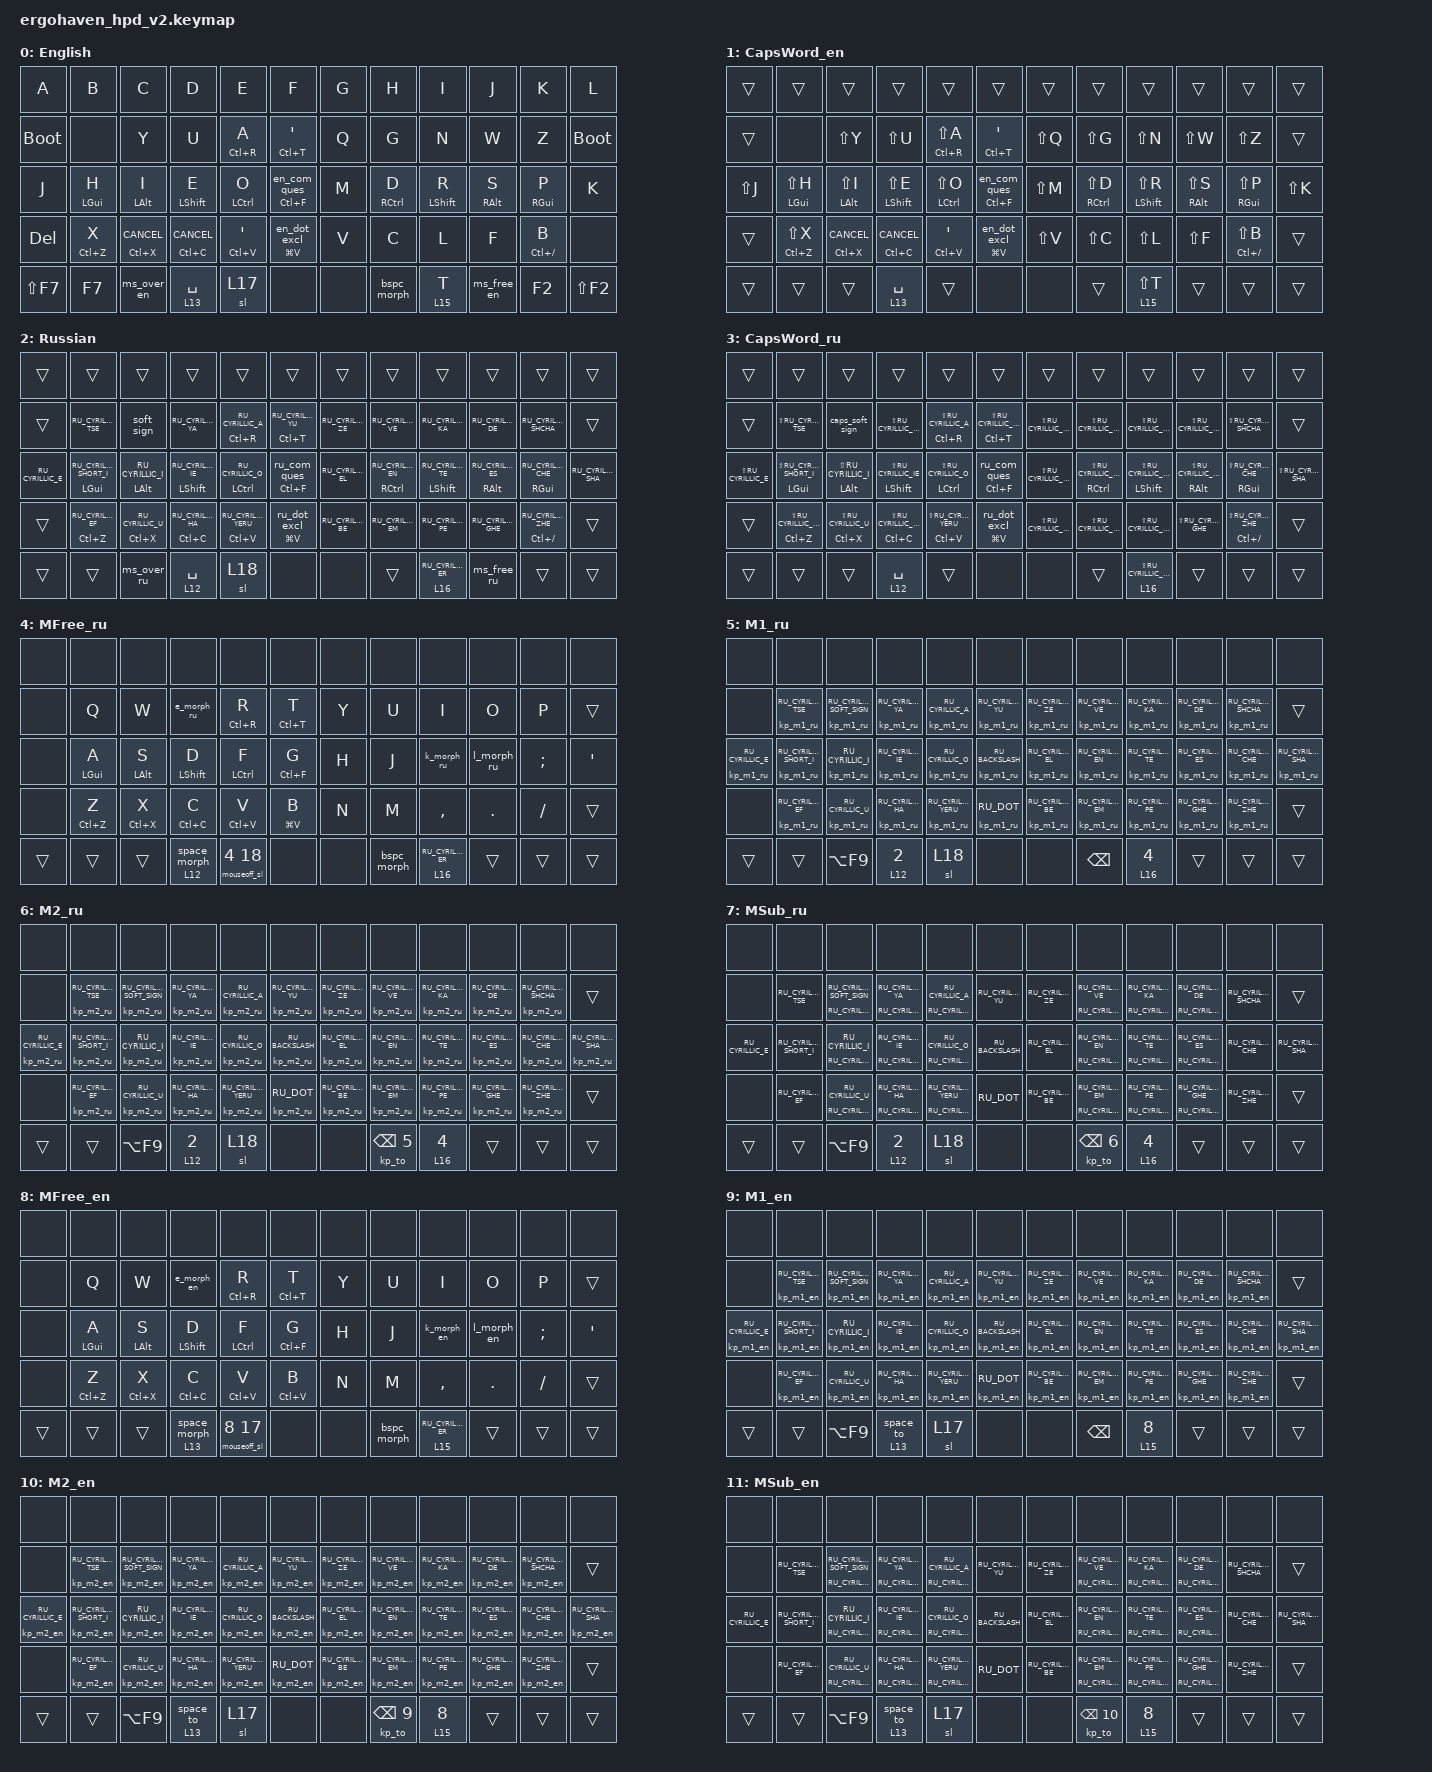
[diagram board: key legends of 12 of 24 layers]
#include "keys_ru.h"
#include <dt-bindings/zmk/behaviors.h>
#include <behaviors.dtsi>
#include <dt-bindings/zmk/keys.h>

&mt {
    flavor = "tap-preferred";
    tapping-term-ms = <200>;
    bindings = <&kp>, <&long_kp>;
};

&lt {
    flavor = "balanced";
    bindings = <&mo>, <&long_kp>;
};

&sl {
    release-after-ms = <5000>;
    ignore-modifiers;
};

&sk {
    release-after-ms = <30000>;
    quick-release;
};

&key_repeat { usage-pages = <HID_USAGE_KEY HID_USAGE_CONSUMER>; };

/ {
    combos {
        compatible = "zmk,combos";

        combo_ctrl_ent {
            bindings = <&long_kp LC(ENTER)>;
            key-positions = <2 4>;
            require-prior-idle-ms = <30>;
        };

        combo_enter {
            bindings = <&long_kp ENTER>;
            key-positions = <3 2>;
            require-prior-idle-ms = <30>;
            timeout-ms = <30>;
        };

        combo_tab {
            bindings = <&long_kp TAB>;
            key-positions = <14 15>;
            require-prior-idle-ms = <50>;
            timeout-ms = <30>;
        };

        combo_esc {
            bindings = <&long_kp ESC>;
            key-positions = <26 27>;
            require-prior-idle-ms = <30>;
            timeout-ms = <30>;
        };

        combo_ru {
            bindings = <&layer_ru>;
            key-positions = <15 16>;
            timeout-ms = <30>;
            require-prior-idle-ms = <50>;
        };

        combo_en {
            bindings = <&layer_en>;
            key-positions = <19 20>;
            timeout-ms = <30>;
            require-prior-idle-ms = <50>;
        };

        combo_osl_sym_en {
            bindings = <&sl 19>;
            key-positions = <21 20>;
            require-prior-idle-ms = <50>;
            layers = <0 1 19>;
            timeout-ms = <30>;
        };

        combo_lessgreater_en {
            bindings = <&less_greater_en>;
            require-prior-idle-ms = <30>;
            key-positions = <31 33>;
            layers = <0 1 19>;
        };

        combo_osl_sym_ru {
            bindings = <&sl 20>;
            key-positions = <20 21>;
            require-prior-idle-ms = <50>;
            layers = <2 3 20>;
            timeout-ms = <30>;
        };

        combo_lessgreater_ru {
            bindings = <&less_greater_ru>;
            key-positions = <31 33>;
            require-prior-idle-ms = <30>;
            layers = <2 3>;
        };

        combo_braces_en {
            bindings = <&braces_en>;
            key-positions = <19 21>;
            require-prior-idle-ms = <50>;
            layers = <0 1 19>;
        };

        combo_asterisk_ru {
            bindings = <&kp RU_ASTERISK>;
            timeout-ms = <30>;
            key-positions = <7 9 8>;
            layers = <2 3 20 16>;
        };

        combo_asterisk_en {
            bindings = <&kp ASTERISK>;
            timeout-ms = <30>;
            key-positions = <7 8 9>;
            layers = <0 1 15 19>;
        };

        combo_capsword_en {
            bindings = <&to 1>;
            key-positions = <14 13>;
            layers = <0 1>;
        };

        combo_osl_fn {
            bindings = <&sl 21>;
            key-positions = <26 28>;
        };

        combo_osl_os_en {
            bindings = <&sl 23>;
            key-positions = <25 26>;
            layers = <0 1 15 19 23 8 9 10 11 17>;
        };

        combo_capsword_ru {
            bindings = <&to 3>;
            key-positions = <14 13>;
            layers = <2 3>;
        };

        combo_plus {
            bindings = <&kp PLUS>;
            key-positions = <7 8>;
        };

        parentheses {
            bindings = <&parentheses>;
            key-positions = <14 16>;
            timeout-ms = <30>;
            require-prior-idle-ms = <50>;
        };

        combo_braces_ru {
            bindings = <&braces_ru>;
            key-positions = <19 21>;
            timeout-ms = <25>;
            layers = <2 3 20>;
            require-prior-idle-ms = <50>;
        };

        combo_brackets_en {
            bindings = <&brackets_en>;
            key-positions = <7 9>;
            layers = <0 1 19>;
            timeout-ms = <30>;
            require-prior-idle-ms = <30>;
        };

        combo_brackets_ru {
            bindings = <&brackets_ru>;
            key-positions = <7 9>;
            layers = <2 3 20>;
            timeout-ms = <30>;
        };

        combo_minus {
            bindings = <&kp MINUS>;
            key-positions = <31 32>;
            require-prior-idle-ms = <30>;
            timeout-ms = <30>;
        };

        combo_ru_at {
            bindings = <&en_kp AT>;
            key-positions = <14 15 16>;
            layers = <2 3 20>;
        };

        combo_en_at {
            bindings = <&kp AT>;
            key-positions = <16 15 14>;
            layers = <0 1 19>;
        };

        combo_quotes_en {
            bindings = <&quote_morph_en>;
            key-positions = <27 28>;
            layers = <0 1 15 19>;
        };

        combo_quotes_ru {
            bindings = <&quote_morph_ru>;
            key-positions = <27 28>;
            layers = <2 3 20 16>;
        };

        combo_slash_ru {
            bindings = <&slash_morph_ru>;
            key-positions = <3 4>;
            layers = <2 3 16 20>;
        };

        combo_slash_en {
            bindings = <&slash_morph_en>;
            key-positions = <3 4>;
            layers = <0 1 15 19>;
        };

        combo_arrow_ru {
            bindings = <&arrow_ru>;
            key-positions = <31 32 33>;
            layers = <2 3 16 20>;
        };

        combo_arrow_en {
            bindings = <&arrow_en>;
            key-positions = <31 33 32>;
            layers = <0 1 15 19>;
        };

        combo_and_ru {
            bindings = <&en_kp AMPERSAND>;
            key-positions = <2 3 4>;
            layers = <2 3 16 20>;
        };

        combo_and_en {
            bindings = <&kp AMPERSAND>;
            key-positions = <2 3 4>;
            layers = <0 1 15 19>;
        };

        combo_dollar_ru {
            bindings = <&en_kp DOLLAR>;
            key-positions = <19 20 21>;
            layers = <2 3 16 20>;
        };

        combo_dollar_en {
            bindings = <&kp DOLLAR>;
            key-positions = <19 20 21>;
            layers = <0 1 15 19>;
        };

        combo_hash_ru {
            bindings = <&en_kp HASH>;
            key-positions = <26 27 28>;
            layers = <2 3 16 20>;
        };

        combo_hash_en {
            bindings = <&kp HASH>;
            key-positions = <26 27 28>;
            layers = <0 1 15 19>;
        };

        cmb_osl_os_ru {
            bindings = <&sl 22>;
            key-positions = <25 26>;
            layers = <2 3 16 20 22 4 5 6 7 18>;
        };

        combo_equal {
            bindings = <&kp EQUAL>;
            key-positions = <8 9>;
        };

        combo_under {
            bindings = <&kp UNDER>;
            key-positions = <32 33>;
        };
    };

    macros {
        layer_ru: layer_ru {
            compatible = "zmk,behavior-macro";
            #binding-cells = <0>;
            bindings = <&kp LS(LC(N8)) &mouse_off &to 2>;
            label = "LAYER_RU";
        };

        layer_en: layer_en {
            compatible = "zmk,behavior-macro";
            #binding-cells = <0>;
            bindings = <&kp LS(LC(N9)) &mouse_off &to 0>;
            label = "LAYER_EN";
        };

        lg_ru: lg_ru {
            compatible = "zmk,behavior-macro";
            #binding-cells = <0>;
            bindings = <&kp LS(LC(N8))>;
            label = "LG_RU";
        };

        lg_en: lg_en {
            compatible = "zmk,behavior-macro";
            #binding-cells = <0>;
            bindings = <&kp LS(LC(N9))>;
            label = "LG_EN";
        };

        en_kp: en_kp {
            compatible = "zmk,behavior-macro-one-param";
            #binding-cells = <1>;
            bindings = <&kp LS(LC(N9)) &macro_param_1to1 &kp MACRO_PLACEHOLDER &kp LS(LC(N8))>;
            label = "EN_KP";
        };

        ru_kp: ru_kp {
            compatible = "zmk,behavior-macro-one-param";
            #binding-cells = <1>;
            bindings = <&kp LS(LC(N8)) &macro_param_1to1 &kp MACRO_PLACEHOLDER &kp LS(LC(N9))>;
            label = "RU_KP";
        };

        mouse_off: mouse_off {
            compatible = "zmk,behavior-macro";
            #binding-cells = <0>;
            bindings = <&kp LA(F12)>;
            label = "MOUSE_OFF";
        };

        free: free {
            compatible = "zmk,behavior-macro";
            #binding-cells = <0>;
            bindings = <&kp LA(F10)>;
            label = "FREE";
        };

        overlay: overlay {
            compatible = "zmk,behavior-macro";
            #binding-cells = <0>;
            bindings = <&kp LA(F11)>;
            label = "OVERLAY";
        };

        select_row: select_row {
            compatible = "zmk,behavior-macro";
            #binding-cells = <0>;
            bindings = <&kp END &kp LS(HOME)>;
            label = "SELECT_ROW";
            wait-ms = <0>;
        };

        en_code: en_code_block {
            compatible = "zmk,behavior-macro";
            #binding-cells = <0>;
            bindings = <&kp GRAVE &kp GRAVE &kp GRAVE &kp RETURN &kp RET &kp GRAVE &kp GRAVE &kp GRAVE &kp UP_ARROW>;
            label = "EN_CODE_BLOCK";
            tap-ms = <50>;
        };

        ru_code: ru_code {
            compatible = "zmk,behavior-macro";
            #binding-cells = <0>;
            bindings = <&lg_en &kp GRAVE &kp GRAVE &kp GRAVE &kp RETURN &kp RET &kp GRAVE &kp GRAVE &kp GRAVE &kp UP_ARROW &lg_ru>;
            label = "RU_CODE";
            tap-ms = <50>;
            wait-ms = <10>;
        };

        ru_cw_off: ru_cw_off {
            compatible = "zmk,behavior-macro-one-param";
            #binding-cells = <1>;
            bindings = <&macro_param_1to1 &kp MACRO_PLACEHOLDER &to 2>;
            label = "RU_CW_OFF";
            wait-ms = <0>;
        };

        en_cw_off: en_cw_off {
            compatible = "zmk,behavior-macro-one-param";
            #binding-cells = <1>;
            bindings = <&macro_param_1to1 &kp MACRO_PLACEHOLDER &to 0>;
            label = "EN_CW_OFF";
            wait-ms = <0>;
        };

        zeros_macro: zeros_macro {
            compatible = "zmk,behavior-macro";
            #binding-cells = <0>;
            bindings = <&kp N0 &kp N0 &kp N0 &kp N0 &kp N0 &kp N0>;
            label = "ZEROS_MACRO";
        };

        ml: ml {
            compatible = "zmk,behavior-macro-one-param";
            #binding-cells = <1>;
            bindings =
                <&macro_param_1to1 &key_on MACRO_PLACEHOLDER &layer_on 14>,
                <&macro_pause_for_release>,
                <&macro_param_1to1 &key_off MACRO_PLACEHOLDER &layer_off 14>;

            label = "Mod Layer";
            wait-ms = <0>;
            tap-ms = <0>;
        };

        quotes_ru: dbl_quote {
            compatible = "zmk,behavior-macro";
            #binding-cells = <0>;
            bindings = <&kp LS(NUMBER_2) &kp LS(NUMBER_2) &kp LEFT_ARROW>;
            label = "DBL_QUOTE";
            wait-ms = <0>;
        };

        quotes_en: quotes_en {
            compatible = "zmk,behavior-macro";
            #binding-cells = <0>;
            bindings = <&kp DOUBLE_QUOTES &kp DOUBLE_QUOTES &kp LEFT_ARROW>;
            label = "QUOTES_EN";
            wait-ms = <0>;
        };

        braces_en: braces_en {
            compatible = "zmk,behavior-macro";
            #binding-cells = <0>;
            bindings = <&kp LEFT_BRACE &kp RIGHT_BRACE &kp LEFT>;
            label = "BRACES_EN";
            wait-ms = <0>;
        };

        braces_ru: braces_ru {
            compatible = "zmk,behavior-macro";
            #binding-cells = <0>;
            bindings = <&lg_en &braces_en &lg_ru>;
            label = "BRACES_RU";
            wait-ms = <0>;
        };

        brackets_en: brackets_en {
            compatible = "zmk,behavior-macro";
            #binding-cells = <0>;
            bindings = <&kp LEFT_BRACKET &kp RIGHT_BRACKET &kp LEFT_ARROW>;
            label = "BRACKETS_EN";
            wait-ms = <0>;
        };

        brackets_ru: brackets_ru {
            compatible = "zmk,behavior-macro";
            #binding-cells = <0>;
            bindings = <&lg_en &brackets_en &lg_ru>;
            label = "BRACKETS_RU";
            wait-ms = <0>;
        };

        parentheses: parentheses {
            compatible = "zmk,behavior-macro";
            #binding-cells = <0>;
            bindings = <&kp LEFT_PARENTHESIS &kp RIGHT_PARENTHESIS &kp LEFT_ARROW>;
            label = "PARENTHESES";
            wait-ms = <0>;
        };

        less_greater_en: less_greater_en {
            compatible = "zmk,behavior-macro";
            #binding-cells = <0>;
            bindings = <&kp LESS_THAN &kp GREATER_THAN &kp LEFT>;
            label = "LESS_GREATER_EN";
            wait-ms = <0>;
        };

        less_greater_ru: less_greater_ru {
            compatible = "zmk,behavior-macro";
            #binding-cells = <0>;
            bindings = <&lg_en &less_greater_en &lg_ru>;
            label = "LESS_GREATER_RU";
        };

        alt_spc_ru: alt_spc_ru {
            compatible = "zmk,behavior-macro";
            #binding-cells = <0>;
            bindings = <&mouse_off &kp LA(SPACE) &to 2>;
            label = "ALT_SPC_RU";
            wait-ms = <0>;
            tap-ms = <40>;
        };

        kp_layeroff: cancel_msoff {
            compatible = "zmk,behavior-macro-two-param";
            #binding-cells = <2>;
            bindings = <&macro_param_1to1 &layer_off MACRO_PLACEHOLDER &macro_param_2to1 &kp MACRO_PLACEHOLDER>;
            label = "CANCEL_MSOFF";
        };

        kp_: kp_ {
            compatible = "zmk,behavior-macro-one-param";
            #binding-cells = <1>;
            bindings =
                <&macro_press>,
                <&macro_param_1to1 &kp MACRO_PLACEHOLDER>,
                <&macro_pause_for_release>,
                <&macro_release>,
                <&macro_param_1to1 &kp MACRO_PLACEHOLDER>;

            label = "KP_";
        };

        testops: testops {
            compatible = "zmk,behavior-macro";
            #binding-cells = <0>;
            bindings =
                <&kp LS(LC(LG(F7)))>,
                <&macro_wait_time 100>,
                <&kp LEFT_ARROW &kp LS(LC(LG(F8)))>;

            label = "TESTOPS";
            wait-ms = <350>;
            tap-ms = <150>;
        };

        long_kp: long_kp {
            compatible = "zmk,behavior-macro-one-param";
            #binding-cells = <1>;
            bindings =
                <&macro_press>,
                <&macro_param_1to1 &kp MACRO_PLACEHOLDER>,
                <&macro_pause_for_release>,
                <&macro_release>,
                <&macro_param_1to1 &kp MACRO_PLACEHOLDER>;

            label = "LONG_KP";
            wait-ms = <50>;
        };

        arrow_en: arrow_en {
            compatible = "zmk,behavior-macro";
            #binding-cells = <0>;
            bindings = <&kp MINUS &kp GREATER_THAN>;
            label = "ARROW_EN";
        };

        arrow_ru: arrow_ru {
            compatible = "zmk,behavior-macro";
            #binding-cells = <0>;
            bindings = <&lg_en &arrow_en &lg_ru>;
            label = "ARROW_RU";
        };

        one_shot: one_shot {
            compatible = "zmk,behavior-macro-one-param";
            #binding-cells = <1>;
            bindings =
                <&macro_param_1to1 &sk MACRO_PLACEHOLDER>,
                <&macro_pause_for_release>,
                <&kp K_CANCEL>;

            label = "ONE_SHOT";
            tap-ms = <10>;
        };

        vm_lang_ru: vm_lang {
            compatible = "zmk,behavior-macro-one-param";
            #binding-cells = <1>;
            bindings = <&macro_param_1to1 &kp MACRO_PLACEHOLDER &lg_ru &lg_ru>;
            label = "VM_LANG";
            wait-ms = <100>;
            tap-ms = <100>;
        };

        vm_lang_en: vm_lang_en {
            compatible = "zmk,behavior-macro-one-param";
            #binding-cells = <1>;
            bindings = <&macro_param_1to1 &kp MACRO_PLACEHOLDER &lg_en &lg_en>;
            label = "VM_LANG_EN";
            wait-ms = <100>;
            tap-ms = <100>;
        };

        ms_free_ru: macro_mless_free {
            compatible = "zmk,behavior-macro";
            #binding-cells = <0>;
            bindings = <&free &to 4>;
            label = "MACRO_MLESS_FREE";
        };

        ms_over_ru: macro_mless_over {
            compatible = "zmk,behavior-macro";
            #binding-cells = <0>;
            bindings = <&overlay &to 5>;
            label = "MACRO_MLESS_OVER";
        };

        ms_free_en: ms_free_en {
            compatible = "zmk,behavior-macro";
            #binding-cells = <0>;
            bindings = <&free &to 8>;
            label = "ms_free_en";
        };

        ms_over_en: ms_over_en {
            compatible = "zmk,behavior-macro";
            #binding-cells = <0>;
            bindings = <&overlay &to 9>;
            label = "ms_over_en";
        };

        kp_m1_ru: kp_m1_ru {
            compatible = "zmk,behavior-macro-one-param";
            #binding-cells = <1>;
            bindings = <&macro_param_1to1 &kp MACRO_PLACEHOLDER &to 6>;
            label = "KP_M1_RU";
        };

        kp_m2_ru: kp_m2_ru {
            compatible = "zmk,behavior-macro-one-param";
            #binding-cells = <1>;
            bindings = <&macro_param_1to1 &kp MACRO_PLACEHOLDER &to 7>;
            label = "kp_m2_ru";
        };

        kp_sub_ru: kp_sub_ru {
            compatible = "zmk,behavior-macro-one-param";
            #binding-cells = <1>;
            bindings = <&macro_param_1to1 &kp MACRO_PLACEHOLDER &to 2>;
            label = "kp_sub_ru";
        };

        kp_to: kp_to {
            compatible = "zmk,behavior-macro-two-param";
            #binding-cells = <2>;
            bindings = <&macro_param_1to1 &kp MACRO_PLACEHOLDER &macro_param_2to1 &to MACRO_PLACEHOLDER>;
            label = "KP_TO";
        };

        kp_m1_en: kp_m1_en {
            compatible = "zmk,behavior-macro-one-param";
            #binding-cells = <1>;
            bindings = <&macro_param_1to1 &kp MACRO_PLACEHOLDER &to 10>;
            label = "KP_M1_EN";
        };

        kp_m2_en: kp_m2_en {
            compatible = "zmk,behavior-macro-one-param";
            #binding-cells = <1>;
            bindings = <&macro_param_1to1 &kp MACRO_PLACEHOLDER &to 11>;
            label = "KP_M2_EN";
        };

        kp_sub_en: kp_sub_en {
            compatible = "zmk,behavior-macro-one-param";
            #binding-cells = <1>;
            bindings = <&macro_param_1to1 &kp MACRO_PLACEHOLDER &to 0>;
            label = "KP_SUB_EN";
        };

        r_to: r_to {
            compatible = "zmk,behavior-macro-one-param";
            #binding-cells = <1>;
            bindings = <&long_kp RU_CYRILLIC_ER &macro_param_1to1 &to MACRO_PLACEHOLDER>;
            label = "R_TO";
        };

        space_to: space_to {
            compatible = "zmk,behavior-macro-one-param";
            #binding-cells = <1>;
            bindings = <&long_kp SPACE &macro_param_1to1 &to MACRO_PLACEHOLDER>;
            label = "SPACE_TO";
        };

        free_move_to: free_move_to {
            compatible = "zmk,behavior-macro-one-param";
            #binding-cells = <1>;
            bindings = <&kp MINUS &free &macro_param_1to1 &to MACRO_PLACEHOLDER>;
            label = "FREE_MOVE_TO";
        };

        alt_spc_en: alt_spc_en {
            compatible = "zmk,behavior-macro";
            #binding-cells = <0>;
            bindings = <&mouse_off &kp LA(SPACE) &to 0>;
            label = "ALT_SPC_EN";
            wait-ms = <0>;
            tap-ms = <40>;
        };

        kp_free: kp_free {
            compatible = "zmk,behavior-macro-one-param";
            #binding-cells = <1>;
            bindings = <&macro_param_1to1 &kp MACRO_PLACEHOLDER &free>;
            label = "KP_FREE";
        };

        mouseoff_sl: mouseoff_sl {
            compatible = "zmk,behavior-macro-two-param";
            #binding-cells = <2>;
            bindings = <&mouse_off &macro_param_1to1 &layer_off MACRO_PLACEHOLDER &macro_param_2to1 &sl MACRO_PLACEHOLDER>;
            label = "MOUSEOFF_SL";
        };

        mouseoff_kp_ru: mouseoff_kp_ru {
            compatible = "zmk,behavior-macro-one-param";
            #binding-cells = <1>;
            bindings = <&mouse_off &macro_param_1to1 &kp MACRO_PLACEHOLDER &to 2>;
            label = "MOUSEOFF_KP_RU";
        };

        mouseoff_kp_en: mouseoff_kp_en {
            compatible = "zmk,behavior-macro-one-param";
            #binding-cells = <1>;
            bindings = <&mouse_off &macro_param_1to1 &kp MACRO_PLACEHOLDER &to 0>;
            label = "MOUSEOFF_KP_EN";
        };

        free_kp: free_kp {
            compatible = "zmk,behavior-macro-one-param";
            #binding-cells = <1>;
            bindings = <&mouse_off &macro_param_1to1 &kp MACRO_PLACEHOLDER &free>;
            label = "FREE_KP";
            wait-ms = <0>;
        };

        drag_sub_ru: drag_sub_ru {
            compatible = "zmk,behavior-macro-one-param";
            #binding-cells = <1>;
            bindings = <&sticky_drag N0 &macro_param_1to1 &kp MACRO_PLACEHOLDER &to 5>;
            label = "DRAG_SUB_RU";
        };

        drag_sub_en: drag_sub_en {
            compatible = "zmk,behavior-macro-one-param";
            #binding-cells = <1>;
            bindings = <&sticky_drag N0 &macro_param_1to1 &kp MACRO_PLACEHOLDER &to 9>;
            label = "DRAG_SUB_EN";
        };
    };

    behaviors {
        layer_off: layer_off {
            compatible = "zmk,behavior-toggle-layer";
            label = "LAYER_OFF";
            #binding-cells = <1>;
            toggle-mode = "off";
        };

        hrm: hrm {
            compatible = "zmk,behavior-hold-tap";
            label = "Home Row Mod";
            bindings = <&kp>, <&kp>;

            #binding-cells = <2>;
            tapping-term-ms = <200>;
            flavor = "balanced";
        };

        hrm_slow: hrm_slow {
            compatible = "zmk,behavior-hold-tap";
            label = "HRM for slow fingers";
            bindings = <&kp>, <&kp>;

            #binding-cells = <2>;
            flavor = "tap-preferred";
            tapping-term-ms = <200>;
        };

        ru_lt_cw_off: ru_lt_cw_off {
            compatible = "zmk,behavior-hold-tap";
            label = "RU_LT_CW_OFF";
            bindings = <&mo>, <&ru_cw_off>;

            #binding-cells = <2>;
            tapping-term-ms = <180>;
            flavor = "balanced";
        };

        en_lt_cw_off: en_lt_cw_off {
            compatible = "zmk,behavior-hold-tap";
            label = "EN_LT_CW_OFF";
            bindings = <&mo>, <&en_cw_off>;

            #binding-cells = <2>;
            tapping-term-ms = <180>;
            flavor = "balanced";
        };

        bspc_morph: bspc_morph {
            compatible = "zmk,behavior-mod-morph";
            label = "BSPC_MORPH";
            bindings = <&kp BACKSPACE>, <&kp DELETE>;

            #binding-cells = <0>;
            mods = <(MOD_LALT)>;
        };

        key_on: key_on {
            compatible = "zmk,behavior-key-toggle";
            label = "KEY_ON";
            #binding-cells = <1>;
        };

        key_off: key_off {
            compatible = "zmk,behavior-key-toggle";
            label = "KEY_OFF";
            #binding-cells = <1>;
            toggle-mode = "off";
        };

        hrml: hrml {
            compatible = "zmk,behavior-hold-tap";
            label = "Home Row Mod Layer";
            bindings = <&ml>, <&kp>;

            #binding-cells = <2>;
            tapping-term-ms = <200>;
            flavor = "balanced";
            hold-trigger-key-positions = <1 2 3 5 6 7 8 9 10 12 13 14 15 16 17 18 19 20 21 22 23 25 26 27 28 29 30 31 32 33 34 42 39 41>;
        };

        layer_on: layer_on {
            compatible = "zmk,behavior-toggle-layer";
            label = "LAYER_ON";
            #binding-cells = <1>;
            toggle-mode = "on";
        };

        hrml_slow: hrml_slow {
            compatible = "zmk,behavior-hold-tap";
            label = "HRML for slow fingers";
            bindings = <&ml>, <&kp>;

            #binding-cells = <2>;
            tapping-term-ms = <200>;
            flavor = "tap-preferred";
        };

        soft_sign: soft_sign {
            compatible = "zmk,behavior-mod-morph";
            label = "SOFT_SIGN";
            bindings = <&kp RU_CYRILLIC_SOFT_SIGN>, <&kp RU_CYRILLIC_HARD_SIGN>;

            #binding-cells = <0>;
            mods = <(MOD_LSFT)>;
        };

        en_dot_excl: en_dot_excl {
            compatible = "zmk,behavior-mod-morph";
            label = "EN_DOT_EXCL";
            bindings = <&morph_en_dot>, <&en_cw_off COLON>;

            #binding-cells = <0>;
            mods = <(MOD_RALT)>;
        };

        en_com_ques: en_com_ques {
            compatible = "zmk,behavior-mod-morph";
            label = "EN_COM_QUES";
            bindings = <&morph_en_com>, <&en_cw_off SEMI>;

            #binding-cells = <0>;
            mods = <(MOD_RALT)>;
        };

        ru_dot_excl: ru_dot_excl {
            compatible = "zmk,behavior-mod-morph";
            label = "RU_DOT_EXCL";
            bindings = <&morph_ru_dot>, <&ru_cw_off RU_COLON>;

            #binding-cells = <0>;
            mods = <(MOD_RALT)>;
        };

        ru_com_ques: ru_com_ques {
            compatible = "zmk,behavior-mod-morph";
            label = "RU_COM_QUES";
            bindings = <&morph_ru_com>, <&ru_cw_off RU_SEMI>;

            #binding-cells = <0>;
            mods = <(MOD_RALT)>;
        };

        ru_dot_mt: ru_dot_mt {
            compatible = "zmk,behavior-hold-tap";
            label = "RU_DOT_MT";
            bindings = <&kp>, <&ru_dot_excl>;

            #binding-cells = <2>;
            tapping-term-ms = <200>;
            flavor = "tap-preferred";
        };

        ru_com_mt: ru_com_mt {
            compatible = "zmk,behavior-hold-tap";
            label = "RU_COM_MT";
            bindings = <&kp>, <&ru_com_ques>;

            #binding-cells = <2>;
            tapping-term-ms = <200>;
            flavor = "tap-preferred";
        };

        en_com_mt: en_com_mt {
            compatible = "zmk,behavior-hold-tap";
            label = "EN_COM_MT";
            bindings = <&kp>, <&en_com_ques>;

            #binding-cells = <2>;
            tapping-term-ms = <200>;
            flavor = "balanced";
        };

        en_dot_mt: en_dot_mt {
            compatible = "zmk,behavior-hold-tap";
            label = "EN_DOT_MT";
            bindings = <&kp>, <&en_dot_excl>;

            #binding-cells = <2>;
            tapping-term-ms = <200>;
            flavor = "balanced";
        };

        space_morph: space_morph {
            compatible = "zmk,behavior-mod-morph";
            label = "SPACE_MORPH";
            bindings = <&kp SPACE>, <&kp TAB>;

            #binding-cells = <0>;
            mods = <(MOD_RSFT|MOD_LALT|MOD_LSFT|MOD_RALT|MOD_LCTL|MOD_RGUI|MOD_RCTL|MOD_LGUI)>;
            keep-mods = <(MOD_LSFT|MOD_RSFT|MOD_LALT|MOD_RALT|MOD_LCTL|MOD_RGUI|MOD_LGUI|MOD_RCTL)>;
        };

        caps_soft_sign: caps_soft_sign {
            compatible = "zmk,behavior-mod-morph";
            label = "CAPS_SOFT_SIGN";
            bindings =
                <&kp LS(RU_CYRILLIC_SOFT_SIGN)>,
                <&kp LS(RU_CYRILLIC_HARD_SIGN)>;

            #binding-cells = <0>;
            mods = <(MOD_LSFT)>;
        };

        space_lt: space_lt {
            compatible = "zmk,behavior-hold-tap";
            label = "SPACE_LT";
            bindings = <&mo>, <&space_morph>;

            #binding-cells = <2>;
            tapping-term-ms = <200>;
            flavor = "balanced";
        };

        mod_dtap: mod_dtap {
            compatible = "zmk,behavior-hold-tap";
            label = "MOD_DTAP";
            bindings = <&kp>, <&kp>;

            #binding-cells = <2>;
            tapping-term-ms = <180>;
            flavor = "hold-preferred";
        };

        hrosm_l: hrosm_l {
            compatible = "zmk,behavior-hold-tap";
            label = "HROSM_L";
            bindings = <&one_shot>, <&kp>;

            #binding-cells = <2>;
            tapping-term-ms = <200>;
            flavor = "balanced";
            hold-trigger-key-positions = <6 18 30 31 32 33 42 19 7 8 20 9 21 22 10 34 23>;
        };

        hrosm_r: hrosm_r {
            compatible = "zmk,behavior-hold-tap";
            label = "HROSM_R";
            bindings = <&one_shot>, <&kp>;

            #binding-cells = <2>;
            tapping-term-ms = <200>;
            flavor = "balanced";
            hold-trigger-key-positions = <12 1 13 25 26 27 28 29 17 16 4 5 3 15 2 14>;
        };

        vm_en: vm_en {
            compatible = "zmk,behavior-hold-tap";
            label = "VM_EN";
            bindings = <&vm_lang_en>, <&vm_lang_en>;

            #binding-cells = <2>;
            tapping-term-ms = <200>;
            flavor = "tap-preferred";
        };

        vm_ru: vm_ru {
            compatible = "zmk,behavior-hold-tap";
            label = "VM_RU";
            bindings = <&vm_lang_ru>, <&vm_lang_ru>;

            #binding-cells = <2>;
            tapping-term-ms = <200>;
            flavor = "tap-preferred";
        };

        space_nav_to: space_nav_to {
            compatible = "zmk,behavior-hold-tap";
            label = "SPACE_NAV_TO";
            bindings = <&mo>, <&space_to>;

            #binding-cells = <2>;
            tapping-term-ms = <200>;
            flavor = "balanced";
        };

        move_nav: move_nav {
            compatible = "zmk,behavior-hold-tap";
            label = "MOVE_NAV";
            bindings = <&mo>, <&free_move_to>;

            #binding-cells = <2>;
            tapping-term-ms = <200>;
            flavor = "balanced";
        };

        sticky_drag: sticky_drag {
            compatible = "zmk,behavior-sticky-key";
            label = "STICKY_DRAG";
            bindings = <&kp>;
            #binding-cells = <1>;
            release-after-ms = <10000>;
            ignore-modifiers;
        };

        mt_mouseoff_ru: mt_mouseoff_ru {
            compatible = "zmk,behavior-hold-tap";
            label = "MT_MOUSEOFF_RU";
            bindings = <&mouseoff_kp_ru>, <&kp>;

            #binding-cells = <2>;
            tapping-term-ms = <200>;
            flavor = "tap-preferred";
        };

        mt_mouseoff_en: mt_mouseoff_en {
            compatible = "zmk,behavior-hold-tap";
            label = "MT_MOUSEOFF_EN";
            bindings = <&mouseoff_kp_en>, <&kp>;

            #binding-cells = <2>;
            tapping-term-ms = <200>;
            flavor = "tap-preferred";
        };

        mt_free: mt_free {
            compatible = "zmk,behavior-hold-tap";
            label = "MT_FREE";
            bindings = <&free_kp>, <&kp>;

            #binding-cells = <2>;
            tapping-term-ms = <200>;
            flavor = "tap-preferred";
        };

        l_morph_ru: l_morph_ru {
            compatible = "zmk,behavior-mod-morph";
            label = "L_MORPH_RU";
            bindings = <&kp L>, <&mouseoff_kp_ru LC(L)>;

            #binding-cells = <0>;
            mods = <(MOD_LCTL)>;
        };

        l_morph_en: l_morph_en {
            compatible = "zmk,behavior-mod-morph";
            label = "L_MORPH_EN";
            bindings = <&kp L>, <&mouseoff_kp_en LC(L)>;

            #binding-cells = <0>;
            mods = <(MOD_LCTL)>;
        };

        e_morph_ru: e_morph_ru {
            compatible = "zmk,behavior-mod-morph";
            label = "E_MORPH_RU";
            bindings = <&kp E>, <&mouseoff_kp_ru LC(E)>;

            #binding-cells = <0>;
            mods = <(MOD_LCTL)>;
        };

        e_morph_en: e_morph_en {
            compatible = "zmk,behavior-mod-morph";
            label = "E_MORPH_EN";
            bindings = <&kp E>, <&mouseoff_kp_en LC(E)>;

            #binding-cells = <0>;
            mods = <(MOD_LCTL)>;
        };

        k_morph_ru: k_morph_ru {
            compatible = "zmk,behavior-mod-morph";
            label = "K_MORPH_RU";
            bindings = <&kp K>, <&mouseoff_kp_ru LC(K)>;

            #binding-cells = <0>;
            mods = <(MOD_LCTL)>;
        };

        k_morph_en: k_morph_en {
            compatible = "zmk,behavior-mod-morph";
            label = "K_MORPH_EN";
            bindings = <&kp K>, <&mouseoff_kp_en LC(K)>;

            #binding-cells = <0>;
            mods = <(MOD_LCTL)>;
        };

        slash_morph_ru: slash_morph_ru {
            compatible = "zmk,behavior-mod-morph";
            label = "SLASH_MORPH_RU";
            bindings = <&morph_pipe_ru>, <&kp RU_BACKSLASH>;

            #binding-cells = <0>;
            mods = <(MOD_LSFT)>;
        };

        slash_morph_en: slash_morph_en {
            compatible = "zmk,behavior-mod-morph";
            label = "SLASH_MORPH_EN";
            bindings = <&morph_pipe_en>, <&kp BACKSLASH>;

            #binding-cells = <0>;
            mods = <(MOD_LSFT)>;
        };

        quote_morph_ru: quote_morph_ru {
            compatible = "zmk,behavior-mod-morph";
            label = "QUOTE_MORPH_RU";
            bindings = <&morph_quotes_ru>, <&en_kp SINGLE_QUOTE>;

            #binding-cells = <0>;
            mods = <(MOD_LSFT)>;
        };

        quote_morph_en: quote_morph_en {
            compatible = "zmk,behavior-mod-morph";
            label = "QUOTE_MORPH_EN";
            bindings = <&morph_quotes_en>, <&kp SINGLE_QUOTE>;

            #binding-cells = <0>;
            mods = <(MOD_LSFT)>;
        };

        mt_sub_ru: mt_sub_ru {
            compatible = "zmk,behavior-hold-tap";
            label = "MT_SUB_RU";
            bindings = <&drag_sub_ru>, <&kp_sub_ru>;

            #binding-cells = <2>;
            tapping-term-ms = <200>;
            flavor = "tap-preferred";
        };

        mt_sub_en: mt_sub_en {
            compatible = "zmk,behavior-hold-tap";
            label = "MT_SUB_EN";
            bindings = <&drag_sub_en>, <&kp_sub_en>;

            #binding-cells = <2>;
            tapping-term-ms = <200>;
            flavor = "tap-preferred";
        };

        semi_morph_ru: semi_morph_ru {
            compatible = "zmk,behavior-mod-morph";
            label = "SEMI_MORPH_RU";
            bindings = <&kp RU_SEMI>, <&kp RU_COLON>;

            #binding-cells = <0>;
            mods = <(MOD_LSFT)>;
        };

        semi_morph_en: semi_morph_en {
            compatible = "zmk,behavior-mod-morph";
            label = "SEMI_MORPH_EN";
            bindings = <&kp SEMI>, <&kp COLON>;

            #binding-cells = <0>;
            mods = <(MOD_LSFT)>;
        };

        morph_en_dot: morph_en_dot {
            compatible = "zmk,behavior-mod-morph";
            label = "MORPH_EN_DOT";
            bindings = <&en_cw_off DOT>, <&en_cw_off EXCL>;

            #binding-cells = <0>;
            mods = <(MOD_LSFT)>;
        };

        morph_en_com: morph_en_com {
            compatible = "zmk,behavior-mod-morph";
            label = "MORPH_EN_COM";
            bindings = <&en_cw_off COMMA>, <&en_cw_off QUESTION>;

            #binding-cells = <0>;
            mods = <(MOD_LSFT)>;
        };

        morph_ru_dot: morph_ru_dot {
            compatible = "zmk,behavior-mod-morph";
            label = "MORPH_RU_DOT";
            bindings = <&ru_cw_off RU_DOT>, <&ru_cw_off RU_EXCL>;

            #binding-cells = <0>;
            mods = <(MOD_LSFT)>;
        };

        morph_ru_com: morph_ru_com {
            compatible = "zmk,behavior-mod-morph";
            label = "MORPH_RU_COM";
            bindings = <&ru_cw_off RU_COMMA>, <&ru_cw_off RU_QUESTION>;

            #binding-cells = <0>;
            mods = <(MOD_LSFT)>;
        };

        morph_quotes_ru: morph_quotes_ru {
            compatible = "zmk,behavior-mod-morph";
            label = "MORPH_QUOTES_RU";
            bindings = <&kp RU_DQT>, <&en_kp GRAVE>;

            #binding-cells = <0>;
            mods = <(MOD_RALT)>;
        };

        morph_quotes_en: morph_quotes_en {
            compatible = "zmk,behavior-mod-morph";
            label = "MORPH_QUOTES_EN";
            bindings = <&kp DQT>, <&kp GRAVE>;

            #binding-cells = <0>;
            mods = <(MOD_RALT)>;
        };

        morph_pipe_ru: morph_pipe_ru {
            compatible = "zmk,behavior-mod-morph";
            label = "MORPH_PIPE_RU";
            bindings = <&kp RU_SLASH>, <&en_kp PIPE>;

            #binding-cells = <0>;
            mods = <(MOD_RALT)>;
        };

        morph_pipe_en: morph_pipe_en {
            compatible = "zmk,behavior-mod-morph";
            label = "MORPH_PIPE_EN";
            bindings = <&kp SLASH>, <&kp PIPE>;

            #binding-cells = <0>;
            mods = <(MOD_RALT)>;
        };
    };

    keymap {
        compatible = "zmk,keymap";

        En {
            bindings = <
&kp A        &kp B                  &kp C                  &kp D                  &kp E          &kp F                   &kp G  &kp H               &kp I                  &kp J            &kp K              &kp L
&bootloader  &none                  &kp Y                  &kp U                  &mt LC(R) A    &mt LC(T) APOS          &kp Q  &kp G               &kp N                  &kp W            &kp Z              &bootloader
&kp J        &hrml_slow LEFT_GUI H  &hrml_slow LEFT_ALT I  &hrosm_l LEFT_SHIFT E  &hrml LCTRL O  &en_com_mt LC(F) 0      &kp M  &hrml_slow RCTRL D  &hrosm_r LEFT_SHIFT R  &hrosm_r RALT S  &hrml_slow RGUI P  &kp K
&kp DELETE   &mt LC(Z) X            &mt LC(X) K_CANCEL     &mt LC(C) K_CANCEL     &mt LC(V) SQT  &en_dot_mt LG(V) 0      &kp V  &kp C               &kp L                  &kp F            &mt LC(SLASH) B    &none
&kp LS(F7)   &kp F7                 &ms_over_en            &lt 13 SPACE           &sl 17         &none                   &none  &bspc_morph         &lt 15 T               &ms_free_en      &kp F2             &kp LS(F2)
            >;

            display-name = "English";
        };

        En_CW {
            bindings = <
&trans     &trans                     &trans                     &trans                     &trans             &trans                  &trans     &trans                  &trans                     &trans               &trans                 &trans
&trans     &none                      &kp LS(Y)                  &kp LS(U)                  &mt LC(R) LS(A)    &mt LC(T) APOS          &kp LS(Q)  &kp LS(G)               &kp LS(N)                  &kp LS(W)            &kp LS(Z)              &trans
&kp LS(J)  &hrml_slow LEFT_GUI LS(H)  &hrml_slow LEFT_ALT LS(I)  &hrosm_l LEFT_SHIFT LS(E)  &hrml LCTRL LS(O)  &en_com_mt LC(F) 0      &kp LS(M)  &hrml_slow RCTRL LS(D)  &hrosm_r LEFT_SHIFT LS(R)  &hrosm_r RALT LS(S)  &hrml_slow RGUI LS(P)  &kp LS(K)
&trans     &mt LC(Z) LS(X)            &mt LC(X) K_CANCEL         &mt LC(C) K_CANCEL         &mt LC(V) SQT      &en_dot_mt LG(V) 0      &kp LS(V)  &kp LS(C)               &kp LS(L)                  &kp LS(F)            &mt LC(SLASH) LS(B)    &trans
&trans     &trans                     &trans                     &en_lt_cw_off 13 SPACE     &trans             &none                   &none      &trans                  &lt 15 LS(T)               &trans               &trans                 &trans
            >;

            display-name = "CapsWord_en";
        };

        Ru {
            bindings = <
&trans             &trans                                   &trans                             &trans                              &trans                      &trans                        &trans              &trans                           &trans                              &trans                        &trans                           &trans
&trans             &kp RU_CYRILLIC_TSE                      &soft_sign                         &kp RU_CYRILLIC_YA                  &mt LC(R) RU_CYRILLIC_A     &mt LC(T) RU_CYRILLIC_YU      &kp RU_CYRILLIC_ZE  &kp RU_CYRILLIC_VE               &kp RU_CYRILLIC_KA                  &kp RU_CYRILLIC_DE            &kp RU_CYRILLIC_SHCHA            &trans
&kp RU_CYRILLIC_E  &hrml_slow LEFT_GUI RU_CYRILLIC_SHORT_I  &hrml_slow LEFT_ALT RU_CYRILLIC_I  &hrosm_l LEFT_SHIFT RU_CYRILLIC_IE  &hrml LCTRL RU_CYRILLIC_O   &ru_com_mt LC(F) 0            &kp RU_CYRILLIC_EL  &hrml_slow RCTRL RU_CYRILLIC_EN  &hrosm_r LEFT_SHIFT RU_CYRILLIC_TE  &hrosm_r RALT RU_CYRILLIC_ES  &hrml_slow RGUI RU_CYRILLIC_CHE  &kp RU_CYRILLIC_SHA
&trans             &mt LC(Z) RU_CYRILLIC_EF                 &mt LC(X) RU_CYRILLIC_U            &mt LC(C) RU_CYRILLIC_HA            &mt LC(V) RU_CYRILLIC_YERU  &ru_dot_mt LG(V) 0            &kp RU_CYRILLIC_BE  &kp RU_CYRILLIC_EM               &kp RU_CYRILLIC_PE                  &kp RU_CYRILLIC_GHE           &mt LC(SLASH) RU_CYRILLIC_ZHE    &trans
&trans             &trans                                   &ms_over_ru                        &lt 12 SPACE                        &sl 18                      &none                         &none               &trans                           &lt 16 RU_CYRILLIC_ER               &ms_free_ru                   &trans                           &trans
            >;

            display-name = "Russian";
        };

        Ru_CW {
            bindings = <
&trans                 &trans                                       &trans                                 &trans                                  &trans                          &trans                            &trans                  &trans                               &trans                                  &trans                            &trans                               &trans
&trans                 &kp LS(RU_CYRILLIC_TSE)                      &caps_soft_sign                        &kp LS(RU_CYRILLIC_YA)                  &mt LC(R) LS(RU_CYRILLIC_A)     &mt LC(T) LS(RU_CYRILLIC_YU)      &kp LS(RU_CYRILLIC_ZE)  &kp LS(RU_CYRILLIC_VE)               &kp LS(RU_CYRILLIC_KA)                  &kp LS(RU_CYRILLIC_DE)            &kp LS(RU_CYRILLIC_SHCHA)            &trans
&kp LS(RU_CYRILLIC_E)  &hrml_slow LEFT_GUI LS(RU_CYRILLIC_SHORT_I)  &hrml_slow LEFT_ALT LS(RU_CYRILLIC_I)  &hrosm_l LEFT_SHIFT LS(RU_CYRILLIC_IE)  &hrml LCTRL LS(RU_CYRILLIC_O)   &ru_com_mt LC(F) 0                &kp LS(RU_CYRILLIC_EL)  &hrml_slow RCTRL LS(RU_CYRILLIC_EN)  &hrosm_r LEFT_SHIFT LS(RU_CYRILLIC_TE)  &hrosm_r RALT LS(RU_CYRILLIC_ES)  &hrml_slow RGUI LS(RU_CYRILLIC_CHE)  &kp LS(RU_CYRILLIC_SHA)
&trans                 &mt LC(Z) LS(RU_CYRILLIC_EF)                 &mt LC(X) LS(RU_CYRILLIC_U)            &mt LC(C) LS(RU_CYRILLIC_HA)            &mt LC(V) LS(RU_CYRILLIC_YERU)  &ru_dot_mt LG(V) 0                &kp LS(RU_CYRILLIC_BE)  &kp LS(RU_CYRILLIC_EM)               &kp LS(RU_CYRILLIC_PE)                  &kp LS(RU_CYRILLIC_GHE)           &mt LC(SLASH) LS(RU_CYRILLIC_ZHE)    &trans
&trans                 &trans                                       &trans                                 &ru_lt_cw_off 12 SPACE                  &trans                          &none                             &none                   &trans                               &lt 16 LS(RU_CYRILLIC_ER)               &trans                            &trans                               &trans
            >;

            display-name = "CapsWord_ru";
        };

        MFree_ru {
            bindings = <
&none   &none                 &none             &none              &none              &none                        &none  &none        &none                  &none        &none      &none
&none   &kp Q                 &kp W             &e_morph_ru        &mt_free LC(R) R   &mt_mouseoff_ru LC(T) T      &kp Y  &kp U        &kp I                  &kp O        &kp P      &trans
&none   &hrm_slow LEFT_GUI A  &hrm_slow LALT S  &hrm_slow LSHFT D  &hrm LCTRL F       &mt_mouseoff_ru LC(F) G      &kp H  &kp J        &k_morph_ru            &l_morph_ru  &kp SEMI   &kp SQT
&none   &mt_free LC(Z) Z      &mt_free LC(X) X  &mt_free LC(C) C   &mt_free LC(V) V   &mt_mouseoff_ru LG(V) B      &kp N  &kp M        &kp COMMA              &kp DOT      &kp SLASH  &trans
&trans  &trans                &trans            &space_lt 12 0     &mouseoff_sl 4 18  &none                        &none  &bspc_morph  &lt 16 RU_CYRILLIC_ER  &trans       &trans     &trans
            >;

            display-name = "MFree_ru";
        };

        M1_ru {
            display-name = "M1_ru";
            bindings = <
&none                    &none                          &none                            &none                     &none                       &none                         &none                     &none                     &none                     &none                      &none                        &none
&none                    &kp_m1_ru RU_CYRILLIC_TSE      &kp_m1_ru RU_CYRILLIC_SOFT_SIGN  &kp_m1_ru RU_CYRILLIC_YA  &kp_m1_ru RU_CYRILLIC_A     &kp_m1_ru RU_CYRILLIC_YU      &kp_m1_ru RU_CYRILLIC_ZE  &kp_m1_ru RU_CYRILLIC_VE  &kp_m1_ru RU_CYRILLIC_KA  &kp_m1_ru RU_CYRILLIC_DE   &kp_m1_ru RU_CYRILLIC_SHCHA  &trans
&kp_m1_ru RU_CYRILLIC_E  &kp_m1_ru RU_CYRILLIC_SHORT_I  &kp_m1_ru RU_CYRILLIC_I          &kp_m1_ru RU_CYRILLIC_IE  &kp_m1_ru RU_CYRILLIC_O     &kp_m1_ru RU_BACKSLASH        &kp_m1_ru RU_CYRILLIC_EL  &kp_m1_ru RU_CYRILLIC_EN  &kp_m1_ru RU_CYRILLIC_TE  &kp_m1_ru RU_CYRILLIC_ES   &kp_m1_ru RU_CYRILLIC_CHE    &kp_m1_ru RU_CYRILLIC_SHA
&none                    &kp_m1_ru RU_CYRILLIC_EF       &kp_m1_ru RU_CYRILLIC_U          &kp_m1_ru RU_CYRILLIC_HA  &kp_m1_ru RU_CYRILLIC_YERU  &kp_m1_ru RU_DOT              &kp_m1_ru RU_CYRILLIC_BE  &kp_m1_ru RU_CYRILLIC_EM  &kp_m1_ru RU_CYRILLIC_PE  &kp_m1_ru RU_CYRILLIC_GHE  &kp_m1_ru RU_CYRILLIC_ZHE    &trans
&trans                   &trans                         &kp LA(F9)                       &space_nav_to 12 2        &sl 18                      &none                         &none                     &kp BSPC                  &move_nav 16 4            &trans                     &trans                       &trans
            >;
        };

        M2_ru {
            display-name = "M2_ru";
            bindings = <
&none                    &none                          &none                            &none                     &none                       &none                         &none                     &none                     &none                     &none                      &none                        &none
&none                    &kp_m2_ru RU_CYRILLIC_TSE      &kp_m2_ru RU_CYRILLIC_SOFT_SIGN  &kp_m2_ru RU_CYRILLIC_YA  &kp_m2_ru RU_CYRILLIC_A     &kp_m2_ru RU_CYRILLIC_YU      &kp_m2_ru RU_CYRILLIC_ZE  &kp_m2_ru RU_CYRILLIC_VE  &kp_m2_ru RU_CYRILLIC_KA  &kp_m2_ru RU_CYRILLIC_DE   &kp_m2_ru RU_CYRILLIC_SHCHA  &trans
&kp_m2_ru RU_CYRILLIC_E  &kp_m2_ru RU_CYRILLIC_SHORT_I  &kp_m2_ru RU_CYRILLIC_I          &kp_m2_ru RU_CYRILLIC_IE  &kp_m2_ru RU_CYRILLIC_O     &kp_m2_ru RU_BACKSLASH        &kp_m2_ru RU_CYRILLIC_EL  &kp_m2_ru RU_CYRILLIC_EN  &kp_m2_ru RU_CYRILLIC_TE  &kp_m2_ru RU_CYRILLIC_ES   &kp_m2_ru RU_CYRILLIC_CHE    &kp_m2_ru RU_CYRILLIC_SHA
&none                    &kp_m2_ru RU_CYRILLIC_EF       &kp_m2_ru RU_CYRILLIC_U          &kp_m2_ru RU_CYRILLIC_HA  &kp_m2_ru RU_CYRILLIC_YERU  &kp_m2_ru RU_DOT              &kp_m2_ru RU_CYRILLIC_BE  &kp_m2_ru RU_CYRILLIC_EM  &kp_m2_ru RU_CYRILLIC_PE  &kp_m2_ru RU_CYRILLIC_GHE  &kp_m2_ru RU_CYRILLIC_ZHE    &trans
&trans                   &trans                         &kp LA(F9)                       &space_nav_to 12 2        &sl 18                      &none                         &none                     &kp_to BSPC 5             &move_nav 16 4            &trans                     &trans                       &trans
            >;
        };

        MSub_ru {
            display-name = "MSub_ru";
            bindings = <
&none              &none                    &none                                                   &none                                     &none                                         &none                   &none               &none                                     &none                                     &none                                       &none                  &none
&none              &kp RU_CYRILLIC_TSE      &mt_sub_ru RU_CYRILLIC_SOFT_SIGN RU_CYRILLIC_SOFT_SIGN  &mt_sub_ru RU_CYRILLIC_YA RU_CYRILLIC_YA  &mt_sub_ru RU_CYRILLIC_A RU_CYRILLIC_A        &kp RU_CYRILLIC_YU      &kp RU_CYRILLIC_ZE  &mt_sub_ru RU_CYRILLIC_VE RU_CYRILLIC_VE  &mt_sub_ru RU_CYRILLIC_KA RU_CYRILLIC_KA  &mt_sub_ru RU_CYRILLIC_DE RU_CYRILLIC_DE    &kp RU_CYRILLIC_SHCHA  &trans
&kp RU_CYRILLIC_E  &kp RU_CYRILLIC_SHORT_I  &mt_sub_ru RU_CYRILLIC_I RU_CYRILLIC_I                  &mt_sub_ru RU_CYRILLIC_IE RU_CYRILLIC_IE  &mt_sub_ru RU_CYRILLIC_O RU_CYRILLIC_O        &kp RU_BACKSLASH        &kp RU_CYRILLIC_EL  &mt_sub_ru RU_CYRILLIC_EN RU_CYRILLIC_EN  &mt_sub_ru RU_CYRILLIC_TE RU_CYRILLIC_TE  &mt_sub_ru RU_CYRILLIC_ES RU_CYRILLIC_ES    &kp RU_CYRILLIC_CHE    &kp RU_CYRILLIC_SHA
&none              &kp RU_CYRILLIC_EF       &mt_sub_ru RU_CYRILLIC_U RU_CYRILLIC_U                  &mt_sub_ru RU_CYRILLIC_HA RU_CYRILLIC_HA  &mt_sub_ru RU_CYRILLIC_YERU RU_CYRILLIC_YERU  &kp RU_DOT              &kp RU_CYRILLIC_BE  &mt_sub_ru RU_CYRILLIC_EM RU_CYRILLIC_EM  &mt_sub_ru RU_CYRILLIC_PE RU_CYRILLIC_PE  &mt_sub_ru RU_CYRILLIC_GHE RU_CYRILLIC_GHE  &kp RU_CYRILLIC_ZHE    &trans
&trans             &trans                   &kp LA(F9)                                              &space_nav_to 12 2                        &sl 18                                        &none                   &none               &kp_to BSPC 6                             &move_nav 16 4                            &trans                                      &trans                 &trans
            >;
        };

        MFree_en {
            display-name = "MFree_en";
            bindings = <
&none   &none                 &none             &none              &none              &none                        &none  &none        &none                  &none        &none      &none
&none   &kp Q                 &kp W             &e_morph_en        &mt_free LC(R) R   &mt_mouseoff_en LC(T) T      &kp Y  &kp U        &kp I                  &kp O        &kp P      &trans
&none   &hrm_slow LEFT_GUI A  &hrm_slow LALT S  &hrm_slow LSHFT D  &hrm LCTRL F       &mt_mouseoff_en LC(F) G      &kp H  &kp J        &k_morph_en            &l_morph_en  &kp SEMI   &kp SQT
&none   &mt_free LC(Z) Z      &mt_free LC(X) X  &mt_free LC(C) C   &mt_free LC(V) V   &mt_mouseoff_en LC(V) B      &kp N  &kp M        &kp COMMA              &kp DOT      &kp SLASH  &trans
&trans  &trans                &trans            &space_lt 13 0     &mouseoff_sl 8 17  &none                        &none  &bspc_morph  &lt 15 RU_CYRILLIC_ER  &trans       &trans     &trans
            >;
        };

        M1_en {
            display-name = "M1_en";
            bindings = <
&none                    &none                          &none                            &none                     &none                       &none                         &none                     &none                     &none                     &none                      &none                        &none
&none                    &kp_m1_en RU_CYRILLIC_TSE      &kp_m1_en RU_CYRILLIC_SOFT_SIGN  &kp_m1_en RU_CYRILLIC_YA  &kp_m1_en RU_CYRILLIC_A     &kp_m1_en RU_CYRILLIC_YU      &kp_m1_en RU_CYRILLIC_ZE  &kp_m1_en RU_CYRILLIC_VE  &kp_m1_en RU_CYRILLIC_KA  &kp_m1_en RU_CYRILLIC_DE   &kp_m1_en RU_CYRILLIC_SHCHA  &trans
&kp_m1_en RU_CYRILLIC_E  &kp_m1_en RU_CYRILLIC_SHORT_I  &kp_m1_en RU_CYRILLIC_I          &kp_m1_en RU_CYRILLIC_IE  &kp_m1_en RU_CYRILLIC_O     &kp_m1_en RU_BACKSLASH        &kp_m1_en RU_CYRILLIC_EL  &kp_m1_en RU_CYRILLIC_EN  &kp_m1_en RU_CYRILLIC_TE  &kp_m1_en RU_CYRILLIC_ES   &kp_m1_en RU_CYRILLIC_CHE    &kp_m1_en RU_CYRILLIC_SHA
&none                    &kp_m1_en RU_CYRILLIC_EF       &kp_m1_en RU_CYRILLIC_U          &kp_m1_en RU_CYRILLIC_HA  &kp_m1_en RU_CYRILLIC_YERU  &kp_m1_en RU_DOT              &kp_m1_en RU_CYRILLIC_BE  &kp_m1_en RU_CYRILLIC_EM  &kp_m1_en RU_CYRILLIC_PE  &kp_m1_en RU_CYRILLIC_GHE  &kp_m1_en RU_CYRILLIC_ZHE    &trans
&trans                   &trans                         &kp LA(F9)                       &space_nav_to 13 0        &sl 17                      &none                         &none                     &kp BSPC                  &move_nav 15 8            &trans                     &trans                       &trans
            >;
        };

        M2_en {
            display-name = "M2_en";
            bindings = <
&none                    &none                          &none                            &none                     &none                       &none                         &none                     &none                     &none                     &none                      &none                        &none
&none                    &kp_m2_en RU_CYRILLIC_TSE      &kp_m2_en RU_CYRILLIC_SOFT_SIGN  &kp_m2_en RU_CYRILLIC_YA  &kp_m2_en RU_CYRILLIC_A     &kp_m2_en RU_CYRILLIC_YU      &kp_m2_en RU_CYRILLIC_ZE  &kp_m2_en RU_CYRILLIC_VE  &kp_m2_en RU_CYRILLIC_KA  &kp_m2_en RU_CYRILLIC_DE   &kp_m2_en RU_CYRILLIC_SHCHA  &trans
&kp_m2_en RU_CYRILLIC_E  &kp_m2_en RU_CYRILLIC_SHORT_I  &kp_m2_en RU_CYRILLIC_I          &kp_m2_en RU_CYRILLIC_IE  &kp_m2_en RU_CYRILLIC_O     &kp_m2_en RU_BACKSLASH        &kp_m2_en RU_CYRILLIC_EL  &kp_m2_en RU_CYRILLIC_EN  &kp_m2_en RU_CYRILLIC_TE  &kp_m2_en RU_CYRILLIC_ES   &kp_m2_en RU_CYRILLIC_CHE    &kp_m2_en RU_CYRILLIC_SHA
&none                    &kp_m2_en RU_CYRILLIC_EF       &kp_m2_en RU_CYRILLIC_U          &kp_m2_en RU_CYRILLIC_HA  &kp_m2_en RU_CYRILLIC_YERU  &kp_m2_en RU_DOT              &kp_m2_en RU_CYRILLIC_BE  &kp_m2_en RU_CYRILLIC_EM  &kp_m2_en RU_CYRILLIC_PE  &kp_m2_en RU_CYRILLIC_GHE  &kp_m2_en RU_CYRILLIC_ZHE    &trans
&trans                   &trans                         &kp LA(F9)                       &space_nav_to 13 0        &sl 17                      &none                         &none                     &kp_to BACKSPACE 9        &move_nav 15 8            &trans                     &trans                       &trans
            >;
        };

        MSub_en {
            display-name = "MSub_en";
            bindings = <
&none              &none                    &none                                                   &none                                     &none                                         &none                   &none               &none                                     &none                                     &none                                       &none                  &none
&none              &kp RU_CYRILLIC_TSE      &mt_sub_en RU_CYRILLIC_SOFT_SIGN RU_CYRILLIC_SOFT_SIGN  &mt_sub_en RU_CYRILLIC_YA RU_CYRILLIC_YA  &mt_sub_en RU_CYRILLIC_A RU_CYRILLIC_A        &kp RU_CYRILLIC_YU      &kp RU_CYRILLIC_ZE  &mt_sub_en RU_CYRILLIC_VE RU_CYRILLIC_VE  &mt_sub_en RU_CYRILLIC_KA RU_CYRILLIC_KA  &mt_sub_en RU_CYRILLIC_DE RU_CYRILLIC_DE    &kp RU_CYRILLIC_SHCHA  &trans
&kp RU_CYRILLIC_E  &kp RU_CYRILLIC_SHORT_I  &mt_sub_en RU_CYRILLIC_I RU_CYRILLIC_I                  &mt_sub_en RU_CYRILLIC_IE RU_CYRILLIC_IE  &mt_sub_en RU_CYRILLIC_O RU_CYRILLIC_O        &kp RU_BACKSLASH        &kp RU_CYRILLIC_EL  &mt_sub_en RU_CYRILLIC_EN RU_CYRILLIC_EN  &mt_sub_en RU_CYRILLIC_TE RU_CYRILLIC_TE  &mt_sub_en RU_CYRILLIC_ES RU_CYRILLIC_ES    &kp RU_CYRILLIC_CHE    &kp RU_CYRILLIC_SHA
&none              &kp RU_CYRILLIC_EF       &mt_sub_en RU_CYRILLIC_U RU_CYRILLIC_U                  &mt_sub_en RU_CYRILLIC_HA RU_CYRILLIC_HA  &mt_sub_en RU_CYRILLIC_YERU RU_CYRILLIC_YERU  &kp RU_DOT              &kp RU_CYRILLIC_BE  &mt_sub_en RU_CYRILLIC_EM RU_CYRILLIC_EM  &mt_sub_en RU_CYRILLIC_PE RU_CYRILLIC_PE  &mt_sub_en RU_CYRILLIC_GHE RU_CYRILLIC_GHE  &kp RU_CYRILLIC_ZHE    &trans
&trans             &trans                   &kp LA(F9)                                              &space_nav_to 13 0                        &sl 17                                        &none                   &none               &kp_to BACKSPACE 10                       &move_nav 15 8                            &trans                                      &trans                 &trans
            >;
        };

        Nav_ru {
            bindings = <
&none   &none                           &none                            &none                    &none                     &none                   &none               &none          &none          &none        &none       &none
&trans  &trans                          &kp LA(LC(GRAVE))                &kp LC(LS(LA(LG(TAB))))  &kp LS(LC(LA(LG(F1))))    &testops                &none               &none          &none          &none        &kp DELETE  &trans
&trans  &hrm LEFT_GUI LC(LEFT_BRACKET)  &hrm LALT LC(RIGHT_BRACKET)      &kp LSHFT                &mod_dtap LCTRL LEFT_GUI  &zeros_macro            &kp K_CONTEXT_MENU  &kp LEFT       &kp DOWN       &kp UP       &kp RIGHT   &trans
&trans  &mt LC(Z) LG(LS(LEFT_BRACKET))  &mt LC(X) LG(LS(RIGHT_BRACKET))  &mt LC(C) LS(F6)         &mt LC(V) LS(LC(LA(V)))   &kp LS(LG(LC(F9)))      &kp LC(F8)          &kp HOME       &kp PAGE_DOWN  &kp PAGE_UP  &kp END     &trans
&trans  &trans                          &trans                           &none                    &none                     &none                   &none               &kp LA(ENTER)  &alt_spc_ru    &trans       &trans      &trans
            >;

            display-name = "Nav_ru";
        };

        Nav_en {
            display-name = "Nav_en";
            bindings = <
&none   &none                           &none                            &none                    &none                     &none                   &none               &none          &none          &none        &none       &none
&trans  &trans                          &kp LA(LC(GRAVE))                &kp LC(LS(LA(LG(TAB))))  &kp LS(LC(LA(LG(F1))))    &testops                &none               &none          &none          &none        &kp DELETE  &trans
&trans  &hrm LEFT_GUI LC(LEFT_BRACKET)  &hrm LALT LC(RIGHT_BRACKET)      &kp LSHFT                &mod_dtap LCTRL LEFT_GUI  &zeros_macro            &kp K_CONTEXT_MENU  &kp LEFT       &kp DOWN       &kp UP       &kp RIGHT   &trans
&trans  &mt LC(Z) LG(LS(LEFT_BRACKET))  &mt LC(X) LG(LS(RIGHT_BRACKET))  &mt LC(C) LS(F6)         &mt LC(V) LS(LC(LA(V)))   &kp LS(LG(LC(F9)))      &kp LC(F8)          &kp HOME       &kp PAGE_DOWN  &kp PAGE_UP  &kp END     &trans
&trans  &trans                          &trans                           &none                    &none                     &none                   &none               &kp LA(ENTER)  &alt_spc_en    &trans       &trans      &trans
            >;
        };

        Mods {
            bindings = <
&none   &none             &none             &none              &none         &none      &none  &none              &none              &none             &none                &none
&trans  &kp Q             &kp W             &kp E              &kp R         &kp T      &kp Y  &kp U              &kp I              &kp O             &kp P                &trans
&trans  &hrm_slow LGUI A  &hrm_slow LALT S  &hrm LEFT_SHIFT D  &hrm LCTRL F  &kp G      &kp H  &hrm_slow RCTRL J  &hrm LEFT_SHIFT K  &hrm_slow RALT L  &hrm_slow RGUI SEMI  &trans
&trans  &kp Z             &kp X             &kp C              &kp V         &kp B      &kp N  &kp M              &kp COMMA          &kp DOT           &kp SLASH            &trans
&trans  &trans            &trans            &space_lt 12 0     &trans        &none      &none  &bspc_morph        &none              &trans            &trans               &trans
            >;

            display-name = "Mod";
        };

        Num_en {
            bindings = <
&none   &none      &none         &none         &none         &none              &none   &none      &none       &none         &none         &none
&trans  &kp MINUS  &kp NUMBER_7  &kp NUMBER_8  &kp N9        &kp PLUS           &trans  &trans     &trans      &trans        &trans        &trans
&trans  &kp N0     &kp N1        &kp N2        &kp NUMBER_3  &morph_en_com      &trans  &kp LCTRL  &kp LSHIFT  &kp LEFT_ALT  &kp LEFT_GUI  &trans
&trans  &kp EQUAL  &kp N4        &kp N5        &kp N6        &morph_en_dot      &trans  &trans     &none       &none         &trans        &trans
&trans  &trans     &trans        &kp SPACE     &none         &none              &none   &trans     &trans      &trans        &trans        &trans
            >;

            display-name = "Num_en";
        };

        Num_ru {
            bindings = <
&none   &none         &none         &none         &none         &none              &none   &none      &none       &none         &none         &none
&trans  &kp MINUS     &kp NUMBER_7  &kp NUMBER_8  &kp N9        &kp PLUS           &trans  &trans     &trans      &trans        &trans        &trans
&trans  &kp NUMBER_0  &kp N1        &kp N2        &kp NUMBER_3  &morph_ru_com      &trans  &kp LCTRL  &kp LSHIFT  &kp LEFT_ALT  &kp LEFT_GUI  &trans
&trans  &kp EQUAL     &kp N4        &kp N5        &kp N6        &morph_ru_dot      &trans  &trans     &none       &none         &trans        &trans
&trans  &trans        &trans        &kp SPACE     &none         &trans             &trans  &trans     &trans      &trans
            >;

            display-name = "Num_ru";
        };

        App_en {
            bindings = <
&none                         &none              &none                                   &none              &none              &none                  &none              &none              &none                  &none                &none                      &none
&trans                        &kp LA(LC(LS(P)))  &vm_en LS(LA(LC(LG(W)))) LS(LA(LC(W)))  &kp LS(LA(LC(E)))  &kp LS(LA(LC(R)))  &kp LS(LA(LC(T)))      &kp LS(LA(LC(Y)))  &kp LS(LA(LC(U)))  &kp LS(LA(LC(I)))      &kp LS(LA(LC(O)))    &kp LS(LA(LC(P)))          &trans
&kp LS(LA(LC(LEFT_BRACKET)))  &kp LS(LA(LC(A)))  &kp LS(LA(LC(S)))                       &kp LS(LA(LC(D)))  &kp LS(LA(LC(F)))  &kp LS(LA(LC(G)))      &kp LS(LA(LC(H)))  &kp LS(LA(LC(J)))  &kp LS(LA(LC(K)))      &kp LS(LA(LC(L)))    &kp LS(LA(LC(SEMICOLON)))  &kp LS(LA(LC(RIGHT_BRACKET)))
&trans                        &kp LS(LC(LA(Z)))  &kp LS(LA(LC(X)))                       &kp LS(LA(LC(C)))  &kp LS(LC(LG(V)))  &kp LS(LA(LC(B)))      &kp LS(LA(LC(N)))  &kp LS(LC(LA(M)))  &kp LS(LA(LC(COMMA)))  &kp LS(LA(LC(DOT)))  &kp LS(LC(LA(SLASH)))      &trans
&trans                        &trans             &trans                                  &none              &sl 17             &none                  &none              &trans             &trans                 &trans               &trans                     &trans
            >;

            display-name = "App_en";
        };

        App_ru {
            display-name = "App_ru";
            bindings = <
&none                         &none              &none                                   &none              &none              &none                  &none              &none              &none                  &none                &none                      &none
&trans                        &kp LA(LC(LS(P)))  &vm_ru LS(LA(LC(LG(W)))) LS(LA(LC(W)))  &kp LS(LA(LC(E)))  &kp LS(LA(LC(R)))  &kp LS(LA(LC(T)))      &kp LS(LA(LC(Y)))  &kp LS(LA(LC(U)))  &kp LS(LA(LC(I)))      &kp LS(LA(LC(O)))    &kp LS(LA(LC(P)))          &trans
&kp LS(LA(LC(LEFT_BRACKET)))  &kp LS(LA(LC(A)))  &kp LS(LA(LC(S)))                       &kp LS(LA(LC(D)))  &kp LS(LA(LC(F)))  &kp LS(LA(LC(G)))      &kp LS(LA(LC(H)))  &kp LS(LA(LC(J)))  &kp LS(LA(LC(K)))      &kp LS(LA(LC(L)))    &kp LS(LA(LC(SEMICOLON)))  &kp LS(LA(LC(RIGHT_BRACKET)))
&trans                        &kp LS(LC(LA(Z)))  &kp LS(LA(LC(X)))                       &kp LS(LA(LC(C)))  &kp LS(LC(LG(V)))  &kp LS(LA(LC(B)))      &kp LS(LA(LC(N)))  &kp LS(LC(LA(M)))  &kp LS(LA(LC(COMMA)))  &kp LS(LA(LC(DOT)))  &kp LS(LC(LA(SLASH)))      &trans
&trans                        &trans             &trans                                  &none              &sl 18             &trans                 &trans             &trans             &trans                 &trans
            >;
        };

        Sym_en {
            bindings = <
&none   &none   &none                 &none        &none                  &none            &none             &none             &none             &none              &none   &none
&trans  &trans  &none                 &none        &none                  &trans           &trans            &kp LEFT_BRACKET  &ru_kp RU_RUBLE   &kp RIGHT_BRACKET  &trans  &trans
&trans  &trans  &kp LEFT_PARENTHESIS  &kp TILDE    &kp RIGHT_PARENTHESIS  &kp PERCENT      &ru_kp RU_NUMERO  &kp LEFT_BRACE    &kp CARET         &kp RIGHT_BRACE    &trans  &trans
&trans  &trans  &none                 &kp PERCENT  &en_code               &none            &trans            &kp LESS_THAN     &ru_kp RU_NUMERO  &kp GREATER_THAN   &trans  &trans
&trans  &trans  &trans                &trans       &trans                 &none            &none             &trans            &trans            &trans             &trans  &trans
            >;

            display-name = "Sym_en";
        };

        Sym_ru {
            bindings = <
&none   &none   &none                 &none           &none     &none               &none          &none                &none          &none                 &none   &none
&trans  &trans  &none                 &none           &none     &trans              &trans         &en_kp LEFT_BRACKET  &kp RU_RUBLE   &en_kp RIGHT_BRACKET  &trans  &trans
&trans  &trans  &kp LEFT_PARENTHESIS  &kp TILDE       &kp RPAR  &kp RU_PERCENT      &kp RU_NUMERO  &en_kp LEFT_BRACE    &en_kp CARET   &en_kp RIGHT_BRACE    &trans  &trans
&trans  &trans  &none                 &kp RU_PERCENT  &ru_code  &none               &trans         &en_kp LESS_THAN     &kp RU_NUMERO  &en_kp GREATER_THAN   &trans  &trans
&trans  &trans  &trans                &trans          &trans    &none               &none          &trans               &trans         &trans                &trans  &trans
            >;

            display-name = "Sym_ru";
        };

        Fn {
            bindings = <
&none   &none    &none   &none   &none   &none        &none   &none      &none           &none     &none         &none
&trans  &trans   &kp F7  &kp F8  &kp F9  &trans       &trans  &trans     &trans          &trans    &trans        &trans
&trans  &kp F10  &kp F1  &kp F2  &kp F3  &kp F12      &trans  &kp LCTRL  &kp LEFT_SHIFT  &kp LALT  &kp LEFT_GUI  &trans
&trans  &kp F11  &kp F4  &kp F5  &kp F6  &trans       &trans  &trans     &trans          &trans    &trans        &trans
&trans  &trans   &trans  &trans  &trans  &none        &none   &trans     &trans          &trans    &trans        &trans
            >;

            display-name = "Fn";
        };

        OS_ru {
            bindings = <
&none   &none   &none           &none                     &none                 &none                     &none   &none    &none   &none   &none   &none
&trans  &trans  &kp LA(LC(N1))  &kp LA(LC(N2))            &kp LC(LA(NUMBER_3))  &kp LC(LA(NUMBER_4))      &trans  &trans   &trans  &trans  &trans  &trans
&trans  &trans  &kp LC(RIGHT)   &kp LA(LC(N1))            &kp C_VOLUME_UP       &kp C_BRI_UP              &trans  &kp F24  &trans  &trans  &trans  &trans
&trans  &trans  &none           &kp LC(LS(LEFT_BRACKET))  &kp C_VOL_DN          &kp C_BRI_DN              &trans  &kp F23  &trans  &trans  &trans  &trans
&trans  &trans  &trans          &trans                    &none                 &none                     &trans  &trans   &trans  &trans  &trans  &trans
            >;

            display-name = "OS_ru";
        };

        OS_en {
            display-name = "OS_en";
            bindings = <
&none   &none   &none           &none                     &none                 &none                     &none   &none    &none   &none   &none   &none
&trans  &trans  &kp LA(LC(N1))  &kp LA(LC(N2))            &kp LC(LA(NUMBER_3))  &kp LC(LA(NUMBER_4))      &trans  &trans   &trans  &trans  &trans  &trans
&trans  &trans  &kp LC(RIGHT)   &kp LA(LC(N1))            &kp C_VOLUME_UP       &kp C_BRI_UP              &trans  &kp F24  &trans  &trans  &trans  &trans
&trans  &trans  &none           &kp LC(LS(LEFT_BRACKET))  &kp C_VOL_DN          &kp C_BRI_DN              &trans  &kp F23  &trans  &trans  &trans  &trans
&trans  &trans  &trans          &trans                    &none                 &none                     &trans  &trans   &trans  &trans  &trans  &trans
            >;
        };
    };
};
